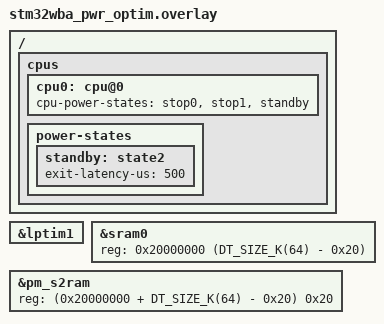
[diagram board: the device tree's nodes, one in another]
/*
 * SPDX-License-Identifier: Apache-2.0
 *
 * Copyright (c) 2025 STMicroelectronics
 */
/ {
	/* Change min residency time to ease power consumption measurement */
	cpus {
		cpu0: cpu@0 {
			cpu-power-states = <&stop0 &stop1 &standby>;
		};

		power-states {
			standby: state2 {
				exit-latency-us = <500>;
			};
		};
	};
};

&lptim1 {
	status = "okay";
};

/*
 * Reduce flash usage for the power-optimized setup so the full flash is
 * not used when it is not necessary, helping reduce power consumption.
 * the pm_S2ram node is moved accordingly to the end of the used flash.
 */
&sram0 {
	reg = <0x20000000 (DT_SIZE_K(64) - 0x20)>;
};

&pm_s2ram {
	reg = <(0x20000000 + DT_SIZE_K(64) - 0x20) 0x20>;
};
